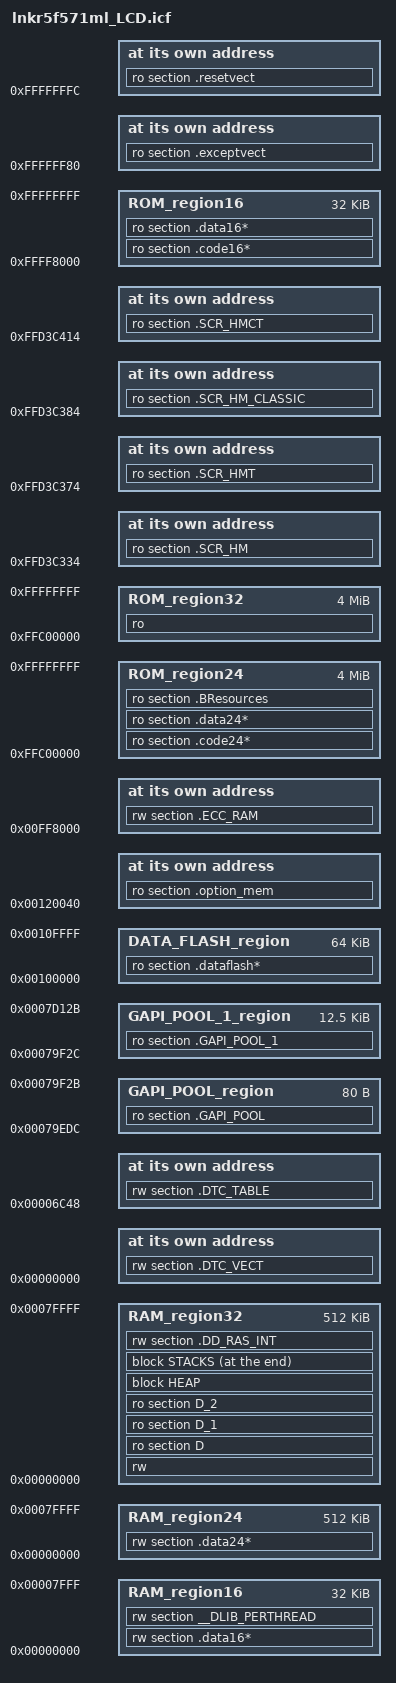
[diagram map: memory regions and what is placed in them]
//-----------------------------------------------------------------------------
// Linker configuration file template for the Renesas RX microcontroller R5F571ML
//-----------------------------------------------------------------------------
// Compatibility check
define exported symbol __link_file_version_4 = 1;

define memory mem with size = 4G;

define region ROM_region16 = mem:[from 0xFFFF8000 to 0xFFFFFFFF];
define region RAM_region16 = mem:[from 0x00000000 to 0x00007FFF];
define region ROM_region24 = mem:[from 0xFFC00000 to 0xFFFFFFFF];
define region RAM_region24 = mem:[from 0x00000000 to 0x0007FFFF];
define region ROM_region32 = mem:[from 0xFFC00000 to 0xFFFFFFFF];
define region RAM_region32 = mem:[from 0x00000000 to 0x0007FFFF];
define region DATA_FLASH_region = mem:[from 0x00100000 to 0x0010FFFF];

initialize manually { rw section .textrw };
initialize by copy { rw, ro section D, ro section D_1, ro section D_2 };
initialize by copy with packing = none { section __DLIB_PERTHREAD };
do not initialize  { section .*.noinit };

define block HEAP     with alignment = 4, size = _HEAP_SIZE { };
define block USTACK   with alignment = 4, size = _USTACK_SIZE { };
define block ISTACK   with alignment = 4, size = _ISTACK_SIZE { };

define block STACKS with fixed order { block USTACK,
                                       block ISTACK };

place at address mem:0x00120040 { ro section .option_mem };

place at address mem:0xFFFFFF80 { ro section .exceptvect };
place at address mem:0xFFFFFFFC { ro section .resetvect };

"ROM16":place in ROM_region16        { ro section .code16*,
                                       ro section .data16* };
"RAM16":place in RAM_region16        { rw section .data16*,
                                       rw section __DLIB_PERTHREAD };
"ROM24":place in ROM_region24        { ro section .code24*,
                                       ro section .data24* };
"RAM24":place in RAM_region24        { rw section .data24* };
"ROM32":place in ROM_region32        { ro };
"RAM32":place in RAM_region32        { rw,
                                       ro section D,
                                       ro section D_1,
                                       ro section D_2,
                                       block HEAP };
"STACKS":place at end of RAM_region32 { block STACKS };

"DATAFLASH":place in DATA_FLASH_region
                                     { ro section .dataflash* };

"DD_RASTERS":place in RAM_region32 { rw section .DD_RAS_INT };
"BResources":place in ROM_region24 { ro section .BResources };

place at address mem:0x00FF8000 {rw section .ECC_RAM };

place at address mem:0x00000000 { rw section .DTC_VECT };
place at address mem:0x00006c48 { rw section .DTC_TABLE };
place at address mem:0xffd3c334 { ro section .SCR_HM };
place at address mem:0xffd3c374 { ro section .SCR_HMT };
place at address mem:0xffd3c384 { ro section .SCR_HM_CLASSIC };
place at address mem:0xffd3c414 { ro section .SCR_HMCT };

define region GAPI_POOL_region = mem:[from 0x00079edc to 0x00079f2b];
"GAPI_POOL":place in GAPI_POOL_region { ro section .GAPI_POOL };

define region GAPI_POOL_1_region = mem:[from 0x00079f2c to 0x0007d12b];
"GAPI_POOL_1":place in GAPI_POOL_1_region { ro section .GAPI_POOL_1 };









